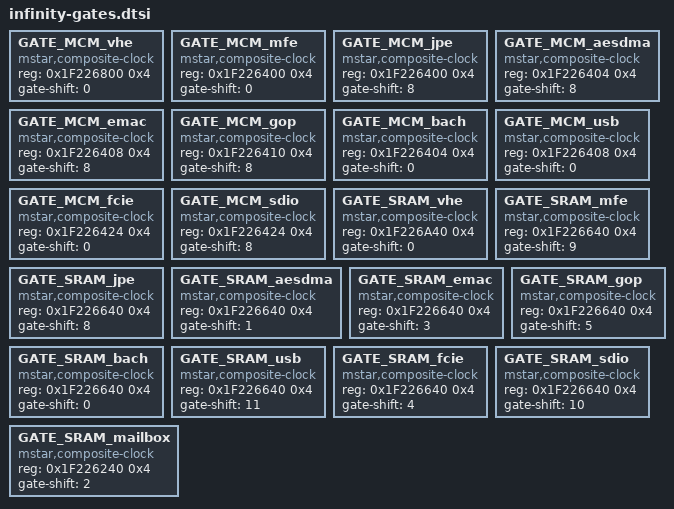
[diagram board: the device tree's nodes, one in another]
GATE_MCM_vhe: GATE_MCM_vhe {
    #clock-cells = <0>;
    compatible = "mstar,composite-clock";
    reg = <0x1F226800 0x4>;
    gate-shift = <0>;
};

GATE_MCM_mfe: GATE_MCM_mfe {
    #clock-cells = <0>;
    compatible = "mstar,composite-clock";
    reg = <0x1F226400 0x4>;
    gate-shift = <0>;
};

GATE_MCM_jpe: GATE_MCM_jpe {
    #clock-cells = <0>;
    compatible = "mstar,composite-clock";
    reg = <0x1F226400 0x4>;
    gate-shift = <8>;
};

GATE_MCM_aesdma: GATE_MCM_aesdma {
    #clock-cells = <0>;
    compatible = "mstar,composite-clock";
    reg = <0x1F226404 0x4>;
    gate-shift = <8>;
};

GATE_MCM_emac: GATE_MCM_emac {
    #clock-cells = <0>;
    compatible = "mstar,composite-clock";
    reg = <0x1F226408 0x4>;
    gate-shift = <8>;
};

GATE_MCM_gop: GATE_MCM_gop {
    #clock-cells = <0>;
    compatible = "mstar,composite-clock";
    reg = <0x1F226410 0x4>;
    gate-shift = <8>;
};

GATE_MCM_bach: GATE_MCM_bach {
    #clock-cells = <0>;
    compatible = "mstar,composite-clock";
    reg = <0x1F226404 0x4>;
    gate-shift = <0>;
};

GATE_MCM_usb: GATE_MCM_usb {
    #clock-cells = <0>;
    compatible = "mstar,composite-clock";
    reg = <0x1F226408 0x4>;
    gate-shift = <0>;
};


GATE_MCM_fcie: GATE_MCM_fcie {
    #clock-cells = <0>;
    compatible = "mstar,composite-clock";
    reg = <0x1F226424 0x4>;
    gate-shift = <0>;
};

GATE_MCM_sdio: GATE_MCM_sdio {
    #clock-cells = <0>;
    compatible = "mstar,composite-clock";
    reg = <0x1F226424 0x4>;
    gate-shift = <8>;
};

/*
GATE_MCM_urdma: GATE_MCM_urdma {
    #clock-cells = <0>;
    compatible = "mstar,composite-clock";
    reg = <0x1F226000 0x4>;
    gate-shift = <8>;
};
*/

GATE_SRAM_vhe: GATE_SRAM_vhe {
    #clock-cells = <0>;
    compatible = "mstar,composite-clock";
    reg = <0x1F226A40 0x4>;
    gate-shift = <0>;
};

GATE_SRAM_mfe: GATE_SRAM_mfe {
    #clock-cells = <0>;
    compatible = "mstar,composite-clock";
    reg = <0x1F226640 0x4>;
    gate-shift = <9>;
};

GATE_SRAM_jpe: GATE_SRAM_jpe {
    #clock-cells = <0>;
    compatible = "mstar,composite-clock";
    reg = <0x1F226640 0x4>;
    gate-shift = <8>;
};

GATE_SRAM_aesdma: GATE_SRAM_aesdma {
    #clock-cells = <0>;
    compatible = "mstar,composite-clock";
    reg = <0x1F226640 0x4>;
    gate-shift = <1>;
};

GATE_SRAM_emac: GATE_SRAM_emac {
    #clock-cells = <0>;
    compatible = "mstar,composite-clock";
    reg = <0x1F226640 0x4>;
    gate-shift = <3>;
};

GATE_SRAM_gop: GATE_SRAM_gop {
    #clock-cells = <0>;
    compatible = "mstar,composite-clock";
    reg = <0x1F226640 0x4>;
    gate-shift = <5>;
};

GATE_SRAM_bach: GATE_SRAM_bach {
    #clock-cells = <0>;
    compatible = "mstar,composite-clock";
    reg = <0x1F226640 0x4>;
    gate-shift = <0>;
};

GATE_SRAM_usb: GATE_SRAM_usb {
    #clock-cells = <0>;
    compatible = "mstar,composite-clock";
    reg = <0x1F226640 0x4>;
    gate-shift = <11>;
};


GATE_SRAM_fcie: GATE_SRAM_fcie {
    #clock-cells = <0>;
    compatible = "mstar,composite-clock";
    reg = <0x1F226640 0x4>;
    gate-shift = <4>;
};

GATE_SRAM_sdio: GATE_SRAM_sdio {
    #clock-cells = <0>;
    compatible = "mstar,composite-clock";
    reg = <0x1F226640 0x4>;
    gate-shift = <10>;
};


GATE_SRAM_mailbox: GATE_SRAM_mailbox {
    #clock-cells = <0>;
    compatible = "mstar,composite-clock";
    reg = <0x1F226240 0x4>;
    gate-shift = <2>;
};
